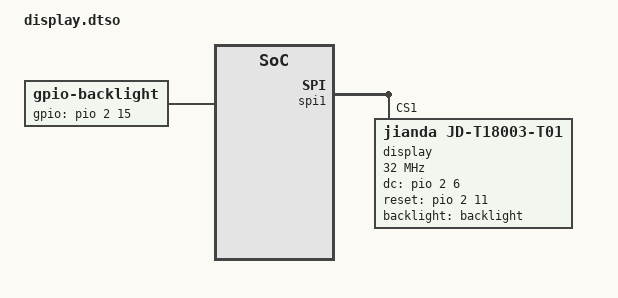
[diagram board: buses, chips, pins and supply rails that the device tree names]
/dts-v1/;
/plugin/;

/ {
    compatible = "xunlong,orangepi-zero3";

    fragment@0 {
        target-path = "/";
        __overlay__ {
            backlight: backlight {
                compatible = "gpio-backlight";
                gpios = <&pio 2 15 0>; /* PC15 - Backlight */
                default-on;
            };
        };
    };

    fragment@1 {
        target = <&spi1>;
        __overlay__ {
            status = "okay";
            #address-cells = <1>;
            #size-cells = <0>;

            pinctrl-names = "default";
            pinctrl-0 = <&spi1_pins &spi1_cs1_pin>; /* PH9 - chip select */

            display@1 {
                compatible = "jianda,jd-t18003-t01";
                reg = <1>;
                spi-max-frequency = <32000000>;

                dc-gpios = <&pio 2 6 0>;     /* PC6 - Data/Command */
                reset-gpios = <&pio 2 11 0>; /* PC11 - Reset */
                rotation = <90>;

                backlight = <&backlight>;
            };
        };
    };
};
